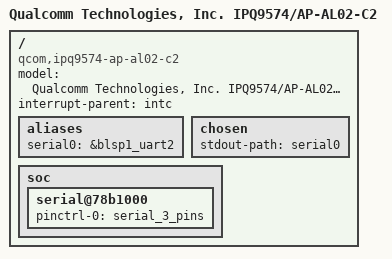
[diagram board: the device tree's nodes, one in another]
// SPDX-License-Identifier: (GPL-2.0+ OR BSD-3-Clause)
/*
 * IPQ9574 AL02-C2 board device tree source
 *
 * Copyright (c) 2020-2021 The Linux Foundation. All rights reserved.
 */

/dts-v1/;

#include "ipq9574.dtsi"
#include "ipq9574-default-memory.dtsi"
#include "ipq9574-cpu.dtsi"

/ {
	#address-cells = <0x2>;
	#size-cells = <0x2>;
	model = "Qualcomm Technologies, Inc. IPQ9574/AP-AL02-C2";
	compatible = "qcom,ipq9574-ap-al02-c2", "qcom,ipq9574-al02", "qcom,ipq9574";
	interrupt-parent = <&intc>;

	aliases {
		serial0 = &blsp1_uart2;
	};

	chosen {
		stdout-path = "serial0";
	};

	soc {
		serial@78b1000 {
			pinctrl-0 = <&serial_3_pins>;
			pinctrl-names = "default";
			status = "ok";
		};
	};
};
